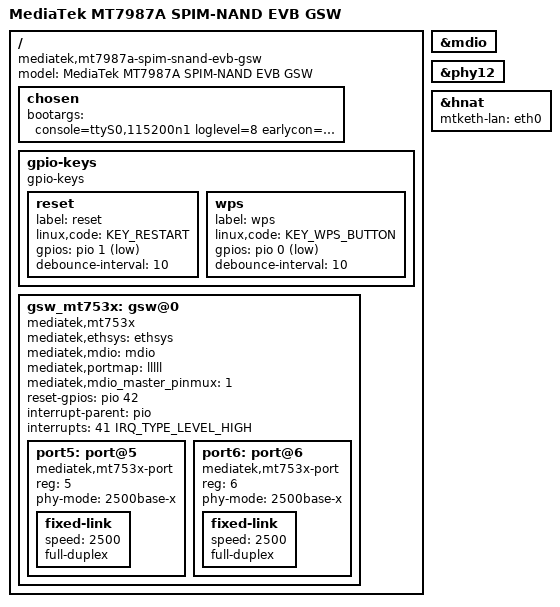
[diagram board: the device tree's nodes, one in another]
/* SPDX-License-Identifier: (GPL-2.0 OR MIT) */

/dts-v1/;
#include "mt7987a.dtsi"
#include "mt7987-netsys-gmac123.dtsi"
#include "mt7987-netsys-gmac1-mt7531.dtsi"
#include "mt7987-spim-nand.dtsi"
#include <dt-bindings/input/input.h>

/ {
	model = "MediaTek MT7987A SPIM-NAND EVB GSW";
	compatible = "mediatek,mt7987a-spim-snand-evb-gsw",
		     "mediatek,mt7987a", "mediatek,mt7987";

	chosen {
		bootargs = "console=ttyS0,115200n1 loglevel=8  \
			    earlycon=uart8250,mmio32,0x11000000 \
			    pci=pcie_bus_perf";
	};

	gpio-keys {
		compatible = "gpio-keys";

		reset {
			label = "reset";
			linux,code = <KEY_RESTART>;
			gpios = <&pio 1 GPIO_ACTIVE_LOW>;
			debounce-interval = <10>;
		};

		wps {
			label = "wps";
			linux,code = <KEY_WPS_BUTTON>;
			gpios = <&pio 0 GPIO_ACTIVE_LOW>;
			debounce-interval = <10>;
		};
	};

	gsw_mt753x: gsw@0 {
		compatible = "mediatek,mt753x";
		mediatek,ethsys = <&ethsys>;
		#address-cells = <1>;
		#size-cells = <0>;
	};
};

&gsw_mt753x {
	mediatek,mdio = <&mdio>;
	mediatek,portmap = "lllll";
	mediatek,mdio_master_pinmux = <1>;
	reset-gpios = <&pio 42 0>;
	interrupt-parent = <&pio>;
	interrupts = <41 IRQ_TYPE_LEVEL_HIGH>;
	status = "okay";

	port5: port@5 {
		compatible = "mediatek,mt753x-port";
		reg = <5>;
		phy-mode = "2500base-x";

		fixed-link {
			speed = <2500>;
			full-duplex;
		};
	};

	port6: port@6 {
		compatible = "mediatek,mt753x-port";
		reg = <6>;
		phy-mode = "2500base-x";

		fixed-link {
			speed = <2500>;
			full-duplex;
		};
	};
};

&mdio {
	/delete-node/ switch@31;
};

&phy12 {
	/delete-property/ airoha,phy-handle;
};

&hnat {
	mtketh-lan = "eth0";
};
